# D1H register map
Vendor: Allwinner; File version: 1.0
Registers are 32-bit, read-write, reset 0x0 unless marked. A register's access mark holds for its fields unless they carry their own. Offsets are from the block's base; [hi:lo] are bit positions; {n}, {i} and the like mark numbered series; 'fields as' and 'values as' point back to an identical list; <NAME> marks a mode.

## AUDIO_CODEC
Base 0x02030000
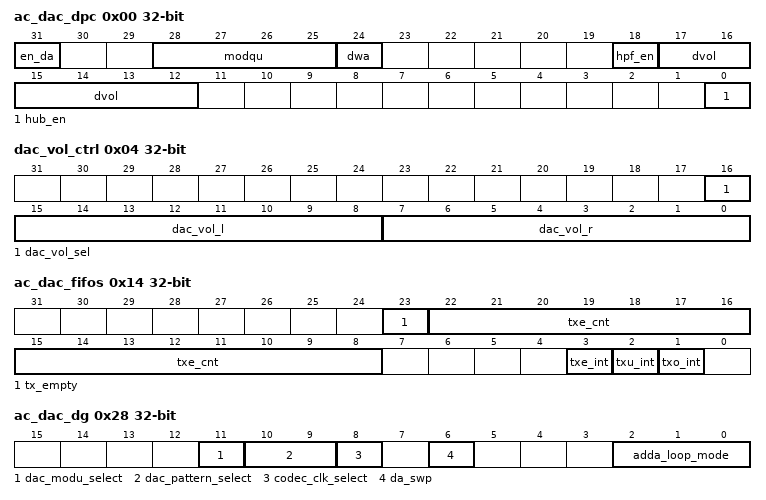
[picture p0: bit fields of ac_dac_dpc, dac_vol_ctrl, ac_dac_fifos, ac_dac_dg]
0x00 ac_dac_dpc — DAC Digital Part Control Register
  [31] en_da — DAC Digital Part Enable
    0=DISABLE; 1=ENABLE
  [28:25] modqu — Internal DAC Quantization Levels. . Levels = [7*(21 + MODQU[3:0])]/128 . Default levels = 7*21/128 = 1.15
  [24] dwa — DWA Function Disable
    0=DISABLE; 1=ENABLE
  [18] hpf_en — High Pass Filter Enable
    0=DISABLE; 1=ENABLE
  [17:12] dvol — Digital Volume Control: DVC . ATT = DVC[5:0] * (-1.16 dB) . 64 steps, -1.16 dB/step
  [0] hub_en — Audio Hub Enable . The bit takes effect only when the EN_DA is set to 1. . System Domain: Audio Codec/I2S0/I2S1/I2S2/OWA TXFIFO Hub Enable.
    0=DISABLE; 1=ENABLE
0x04 dac_vol_ctrl — DAC Volume Control Register
  [16] dac_vol_sel — DAC Volume Control Selection Enable
    0=DISABLE; 1=ENABLE
  [15:8] dac_vol_l — DAC left channel volum (-119.25 dB to 71.25 dB, 0.75 dB/Step) . 0x00: Mute . 0x01: -119.25 dB ... . 0x9F = -0.75 dB . 0xA0 = 0 dB . 0xA1 = 0.75 dB ... . 0xFF = 71.25 dBe
  [7:0] dac_vol_r — DAC right channel volum (-119.25 dB to 71.25 dB, 0.75 dB/Step) . 0x00: Mute . 0x01: -119.25 dB ... . 0x9F = -0.75 dB . 0xA0 = 0 dB . 0xA1 = 0.75 dB ... . 0xFF = 71.25 dBe
0x10 ac_dac_fifoc — DAC FIFO Control Register
  [31:29] dac_fs — Sample Rate of DAC
    0=FS48K; 1=FS32K; 2=FS24K; 3=FS16K; 4=FS12K; 5=FS8K; 6=FS192K; 7=FS96K
  [28] fir_ver — FIR Version
    0=TAP_64; 1=TAP_32
  [26] send_last — Audio sample select when TX FIFO underrun
    0=ZERO; 1=LAST
  [25:24] fifo_mode
    0=BIG_ENDIAN; 1=LITTLE_ENDIAN
  [14:8] dac_drq_clr_cnt — DAC DRQ clear count
    0=WLEVEL; 1=N4; 2=N8; 3=N16
  [14:8] tx_trig_level — TX FIFO Empty Trigger Level
  [6] dac_mono_en — DAC Mono Enable
    0=STEREO; 1=MONO
  [5] tx_sample_bits — Transmitting Audio Sample Resolution
    0=BITS_16; 1=BITS_20
  [4] dac_drq_en — DAC FIFO Empty DRQ Enable
    0=DISABLE; 1=ENABLE
  [3] dac_irq_en — DAC FIFO Empty IRQ Enable
    0=DISABLE; 1=ENABLE
  [2] fifo_underrun_irq_en — DAC FIFO Underrun IRQ Enable
    0=DISABLE; 1=ENABLE
  [1] fifo_overrun_irq_en — DAC FIFO Overrun IRQ Enable
    0=DISABLE; 1=ENABLE
  [0] fifo_flush — DAC FIFO Flush
    0=SELF_CLEAR; 1=FLUSH
0x14 ac_dac_fifos — DAC FIFO Status Register
  [23] tx_empty ro — TX FIFO Empty
    0=NO_ROOM; 1=ROOM
  [22:8] txe_cnt ro — TX FIFO Empty Space Word Counter
  [3] txe_int — TX FIFO Empty Pending Interrupt
    0=NO_PENDING; 1=PENDING
  [2] txu_int — TX FIFO Underrun Pending Interrupt
    0=NO_PENDING; 1=PENDING
  [1] txo_int — TX FIFO Overrun Pending Interrupt
    0=NO_PENDING; 1=PENDING
0x20 ac_dac_txdata wo — DAC TX DATA Register
  [31:0] tx_data — Write the transmitting left and right channel sample data to this register one by one. Write the left channel sample data first and then the right channel sample.
0x24 ac_dac_cnt — DAC TX FIFO Counter Register
  [31:0] tx_cnt — TX Sample Counter . The audio sample number of sending into TXFIFO. . When one sample is put into TXFIFO by DMA or by host IO, the TX sample counter register increases by one. The TX sample counter register can be set to any initial valve at any time. After being updated by the initial value, the counter register should count from this initial value.
0x28 ac_dac_dg — DAC Debug Register
  [11] dac_modu_select — DAC Modulator Debug Mode
    0=NORMAL; 1=DEBUG
  [10:9] dac_pattern_select
    0=NORMAL (Normal (Audio sample from TX FIFO)); 1=SIN6 (-6 dB Sin wave); 2=SIN60 (-60 dB Sin wave); 3=SILENT (Silent wave)
  [8] codec_clk_select — CODEC Clock Source Select
    0=PLL (CODEC clock from PLL); 1=OSC (CODEC clock from OSC (for Debug))
  [6] da_swp — DAC Output Channel Swap Enable
    0=DISABLE; 1=ENABLE
  [2:0] adda_loop_mode — ADDA Loop Mode Select
    0=DISABLE; 1=ADC12 (ADDA LOOP MODE DACL/DACR is connected to ADC1/ADC2); 2=ADC3 (ADDA LOOP MODE DACL/DACR is connected to ADC3)
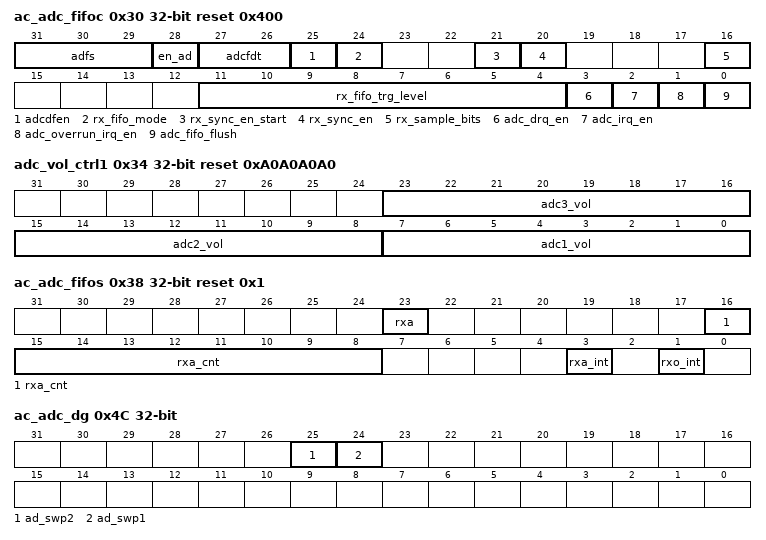
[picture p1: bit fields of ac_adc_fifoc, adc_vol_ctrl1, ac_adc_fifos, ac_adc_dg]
0x30 ac_adc_fifoc reset 0x400 — ADC FIFO Control Register
  [31:29] adfs — Sample Rate of ADC . 44.1 kHz/22.05 kHz/11.025 kHz can be supported by Audio PLL Configure Bit.
    0=48KHZ; 2=24KHZ; 4=12KHZ; 1=32KHZ; 3=16KHZ; 5=8KHZ; 7=R_ESERVED
  [28] en_ad — ADC Digital Part Enable
    0=DISABLED; 1=ENABLED
  [27:26] adcfdt — ADC FIFO delay time for writing data after EN_AD
    0=5_MS; 1=10_MS; 2=20_MS; 3=30_MS
  [25] adcdfen — ADC FIFO delay function for writing data after EN_AD
    0=DISABLED; 1=ENABLED
  [24] rx_fifo_mode — RX FIFO Output Mode (Mode 0, 1) . For 20-bit received audio sample: . Mode 0: RXDATA[31:0] = {FIFO_O[19:0], 12'h0} . Mode 1: RXDATA[31:0] = {12{FIFO_O[19]}, FIFO_O[19:0]} . For 16-bit received audio sample: . Mode 0: RXDATA[31:0] = {FIFO_O[19:4], 16'h0} . Mode 1: RXDATA[31:0] = {16{FIFO_O[19]}, FIFO_O[19:4]}
    0=E_XPANDING_ZERO (Expanding '0' at LSB of TX FIFO register); 1=E_XPANDING_SIGN (Expanding received sample sign bit at MSB of TX FIFO register)
  [21] rx_sync_en_start — The bit takes effect only when RX_SYNC_EN is set to 1. System Domain: Audio codec/I2S0/I2S1/I2S2/DMIC/OWA RX Synchronize Enable Start.
    0=DISABLED; 1=ENABLED
  [20] rx_sync_en — Audiocodec RX Synchronize Enable
    0=DISABLED; 1=ENABLED
  [16] rx_sample_bits — Receiving Audio Sample Resolution
    0=16_BITS; 1=20_BITS
  [11:4] rx_fifo_trg_level — RX FIFO Trigger Level (RXTL[5:0]) . Interrupt and DMA request trigger level for RX FIFO normal condition IRQ/DRQ generated when WLEVEL > RXTL[5:0]
  [3] adc_drq_en — ADC FIFO Data Available DRQ Enable
    0=DISABLED; 1=ENABLED
  [2] adc_irq_en — ADC FIFO Data Available IRQ Enable
    0=DISABLED; 1=ENABLED
  [1] adc_overrun_irq_en — ADC FIFO Overrun IRQ Enable
    0=DISABLED; 1=ENABLED
  [0] adc_fifo_flush write-clears — ADC FIFO Flush . Write '1' to flush TX FIFO, self clear to '0'.
0x34 adc_vol_ctrl1 reset 0xA0A0A0A0 — ADC Volume Control1 Register
  [8n-1:8n-8] adc{n}_vol (n=1..3) — ADC[i] channel volume (-119.25 dB To 71.25 dB, 0.75 dB/Step)
    0=M_UTE; 1=N_119_25DB (-119.25 dB ...); 160=0DB; 255=71_25DB
0x38 ac_adc_fifos reset 0x1 — ADC FIFO Status Register
  [23] rxa ro — RX FIFO Available
    0=NO_AVAILABLE (No available data in RX FIFO); 1=MORE (More than one sample in RX FIFO (>= 1 word))
  [16:8] rxa_cnt ro — RX FIFO Available Sample Word Counter
  [3] rxa_int write-1-clears — RX FIFO Data Available Pending Interrupt
    0=NO_PENDING (No Pending IRQ); 1=PENDING (Data Available Pending IRQ . Write '1' to clear this interrupt or automatic clear if the interrupt condition fails.)
  [1] rxo_int write-1-clears — RX FIFO Overrun Pending Interrupt
    0=NO_PENDING (No Pending IRQ); 1=PENDING (FIFO Overrun Pending IRQ . Write '1' to clear this interrupt.)
0x40 ac_adc_rxdata — ADC RX Data Register
  [31:0] rx_data ro — RX Sample . The host can get one sample by reading this register. The left channel sample data comes first and then the right channel sample.
0x44 ac_adc_cnt — ADC RX Counter Register
  [31:0] rx_cnt — RX Sample Counter . The audio sample number of writing into RXFIFO. When one sample is written by Digital Audio Engine, the RX sample counter register increases by one. The RX sample counter register can be set to any initial valve at any time. After being updated by the initial value, the counter register should count from this initial value.
0x4C ac_adc_dg — ADC Debug Register
  [25] ad_swp2 — ADC output channel swap enable (for digital filter)
    0=DISABLED; 1=ENABLED
  [24] ad_swp1 — ADC output channel swap enable (for digital filter)
    0=DISABLED; 1=ENABLED
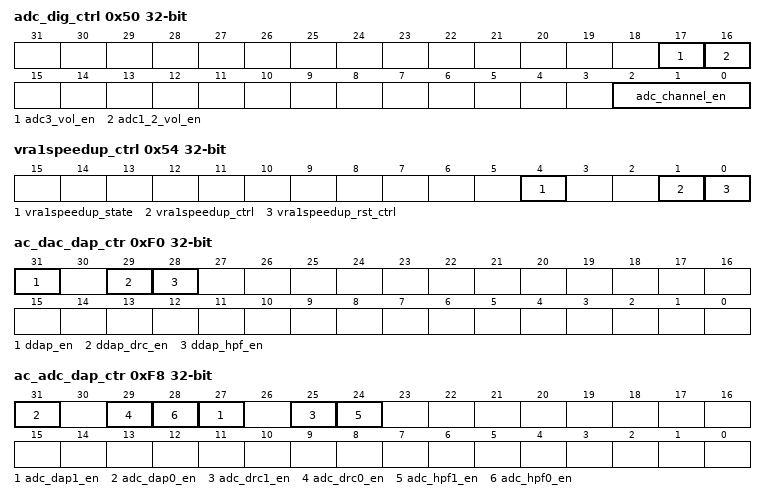
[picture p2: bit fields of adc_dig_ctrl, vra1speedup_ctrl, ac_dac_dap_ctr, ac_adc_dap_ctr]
0x50 adc_dig_ctrl — ADC Digtial Control Register
  [17] adc3_vol_en — ADC3 Volume Control Enable
    0=DISABLED; 1=ENABLED
  [16] adc1_2_vol_en — ADC1/2 Volume Control Enable
    0=DISABLED; 1=ENABLED
  [2:0] adc_channel_en — Bit 3: ADC4 enabled . Bit 2: ADC3 enabled . Bit 1: ADC2 enabled . Bit 0: ADC1 enabled
0x54 vra1speedup_ctrl — VRA1 Speedup Down Control Register
  [4] vra1speedup_state ro — Only if VAR1SPEEDUP_Further_CTRL (0x310[22]) is set 0, VAR1Speedup Down State is valid.
    0=NOT_WORK (VAR1Speedup_Down does not work.); 1=WORK (VAR1Speedup_Down works.)
  [1] vra1speedup_ctrl — VAR1Speedup Down Manual Control Enable
    0=DISABLED (Disabled. . VAR1Speedup Down converts to 1 after the bus rst releases 32 ms.); 1=ENABLED (Enabled. . VAR1Speedup Down converts to 1 immediately.)
  [0] vra1speedup_rst_ctrl — VAR1Speedup Down RST Manual Control Enable
    0=DISABLED (Disabled. . VAR1Speedup Down converts to 1 after the bus rst releases 32 ms.); 1=ENABLED (Enabled. . VAR1Speedup Down reset 0 immediately.)
0xF0 ac_dac_dap_ctr — DAC DAP Control Register
  [31] ddap_en — DAP for DRC enable
    0=BYPASSED; 1=ENABLED
  [29] ddap_drc_en — DRC enable control
    0=DISABLED; 1=ENABLED
  [28] ddap_hpf_en — HPF enable control
    0=DISABLED; 1=ENABLED
0xF8 ac_adc_dap_ctr — ADC DAP Control Register
  [27] adc_dap{x}_en (x=1,0; step 4) — DAP[i] for ADC enable . DAP0 control ADC1/2 . DAP1 control ADC3
    0=BYPASSED; 1=ENABLED
  [25] adc_drc{x}_en (x=1,0; step 4) — ADC DRC[i] enable control
    0=DISABLED; 1=ENABLED
  [24] adc_hpf{x}_en (x=1,0; step 4) — ADC HPF[i] enable control
    0=DISABLED; 1=ENABLED
0x100 ac_dac_drc_hhpfc reset 0xFF — DAC DRC High HPF Coef Register
  [10:0] hhpfc — HPF coefficient setting and the data is 3.24 format.
0x104 ac_dac_drc_lhpfc reset 0xFAC1 — DAC DRC Low HPF Coef Register
  [15:0] lhpfc — HPF coefficient setting and the data is 3.24 format.
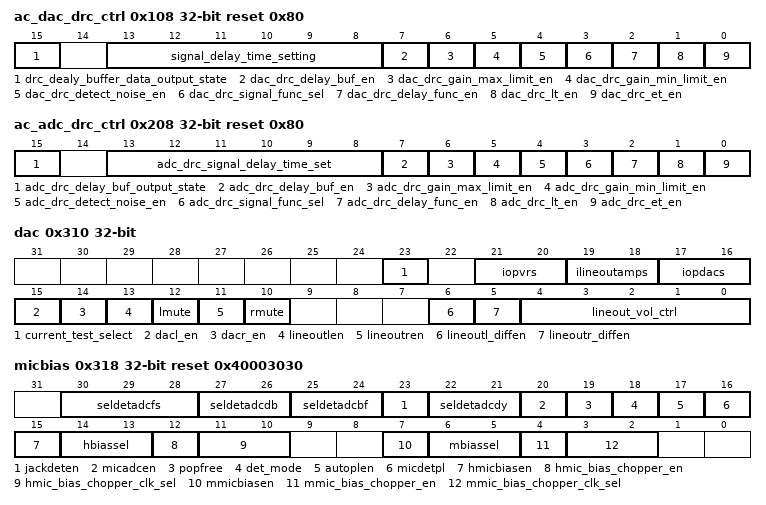
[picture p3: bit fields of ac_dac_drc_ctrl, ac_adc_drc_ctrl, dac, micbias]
0x108 ac_dac_drc_ctrl reset 0x80 — DAC DRC Control Register
  [15] drc_dealy_buffer_data_output_state ro — DRC delay buffer data output state when The DRC delay function is enabled and the DRC function is disabled. After disabling the DRC function and this bit goes to 0, write the DRC delay function bit to 0.
    0=NOT_COMPLETED; 1=COMPLETED
  [13:8] signal_delay_time_setting — Signal delay time setting . Delay time = 8*(n + 1) fs, n less than 30 . When the delay function is disabled, the signal delay time is unused.
  [7] dac_drc_delay_buf_en — The delay buffer use or not when the DRC is disabled and the DRC buffer data output completely.
    0=D_O_NOT_USE_THE_BUFFER; 1=U_SE_THE_BUFFER
  [6] dac_drc_gain_max_limit_en — DRC gain max limit enable
    0=DISABLED; 1=ENABLED
  [5] dac_drc_gain_min_limit_en — DRC gain min limit enable When this function is enabled, it will overwrite the noise detect function.
    0=DISABLED; 1=ENABLED
  [4] dac_drc_detect_noise_en — Control the DRC to detect noise when ET is enabled.
    0=DISABLED; 1=ENABLED
  [3] dac_drc_signal_func_sel — Signal function select . When the signal function selects the Peak filter, the RMS parameter is unused. (AC_DRC_LRMSHAT, AC_DRC_LRMSLAT, AC_DRC_LRMSHAT, AC_DRC_LRMSLAT) . When the signal function selects the RMS filter, the Peak filter parameter is unused. (AC_DRC_LPFHAT, AC_DRC_LPFLAT, AC_DRC_RPFHAT, AC_DRC_RPFLAT, AC_DRC_LPFHRT, AC_DRC_LPFLRT, AC_DRC_RPFHRT, and AC_DRC_RPFLRT)
    0=RMS (RMS filter); 1=P_EAK (Peak filter)
  [2] dac_drc_delay_func_en — Delay function enable
    0=DISABLED; 1=ENABLED (Enabled . When the bit is disabled, the signal delay time is unused.)
  [1] dac_drc_lt_en — DRC LT enable
    0=DISABLED; 1=ENABLED (Enabled . When the bit is disabled, Kl and OPL parameter is unused.)
  [0] dac_drc_et_en — DRC ET enable
    0=DISABLED; 1=ENABLED (Enabled . When the bit is disabled, Ke and OPE parameter is unused.)
0x10C ac_dac_drc_lpfhat reset 0xB — DAC DRC Left Peak Filter High Attack Time Coef Register
  [10:0] dac_drc_lpfhat — The left peak filter attack time parameter setting, which is determined by the equation that AT = 1-exp (-2.2Ts/ta). The format is 3.24. (The default value is 1 ms)
0x110 ac_dac_drc_lpflat reset 0x77BF — DAC DRC Left Peak Filter Low Attack Time Coef Register
  [15:0] dac_drc_lpflat — The left peak filter attack time parameter setting, which is determined by the equation that AT = 1-exp (-2.2Ts/ta). The format is 3.24. (The default value is 1 ms)
0x114 ac_dac_drc_rpfhat reset 0xB — DAC DRC Right Peak Filter High Attack Time Coef Register
  [15:0] dac_drc_rpfhat — The right peak filter attack time parameter setting, which is determined by the equation that AT = 1-exp (-2.2Ts/ta). The format is 3.24. (The default value is 1 ms)
0x118 ac_dac_drc_rpflat reset 0x77BF — DAC DRC Peak Filter Low Attack Time Coef Register
  [15:0] dac_drc_rpflat — The left peak filter attack time parameter setting, which is determined by the equation that AT = 1-exp (-2.2Ts/ta). The format is 3.24. (The default value is 1 ms)
0x11C ac_dac_drc_lpfhrt reset 0xFF — DAC DRC Left Peak Filter High Release Time Coef Register
  [10:0] dac_drc_lpfhrt — The left peak filter release time parameter setting, which is determined by the equation that RT = exp (-2.2Ts/tr). The format is 3.24. (The default value is 100 ms)
0x120 ac_dac_drc_lpflrt reset 0xE1F8 — DAC DRC Left Peak Filter Low Release Time Coef Register
  [15:0] dac_drc_lpflrt — The left peak filter release time parameter setting, which is determined by the equation that RT = exp (-2.2Ts/tr). The format is 3.24. (The default value is 100 ms)
0x124 ac_dac_drc_rpfhrt reset 0xFF — DAC DRC Right Peak filter High Release Time Coef Register
  [15:0] dac_drc_rpfhrt — The right peak filter release time parameter setting, which is determined by the equation that RT = exp (-2.2Ts/tr). The format is 3.24. (The default value is 100 ms)
0x128 ac_dac_drc_rpflrt reset 0xE1F8 — DAC DRC Right Peak filter Low Release Time Coef Register
  [15:0] dac_drc_rpflrt — The right peak filter release time parameter setting, which is determined by the equation that AT = exp(-2.2Ts/tr). The format is 3.24. (The default value is 100 ms)
0x12C ac_dac_drc_lrmshat reset 0x1 — DAC DRC Left RMS Filter High Coef Register
  [10:0] dac_drc_lrmshat — The left RMS filter average time parameter setting, which is determined by the equation that AT = 1-exp (-2.2Ts/tav). The format is 3.24. (The default value is 10 ms)
0x130 ac_dac_drc_lrmslat reset 0x2BAF — DAC DRC Left RMS Filter Low Coef Register
  [15:0] dac_drc_lrmslat — The left RMS filter average time parameter setting, which is determined by the equation that AT = 1-exp (-2.2Ts/tav). The format is 3.24. (The default value is 10 ms)
0x134 ac_dac_drc_rrmshat reset 0x2BAF — DAC DRC Right RMS Filter High Coef Register
  [15:0] dac_drc_rrmshat — The right RMS filter average time parameter setting, which is determined by the equation that AT = 1-exp (-2.2Ts/tav). The format is 3.24. (The default value is 10 ms)
0x138 ac_dac_drc_rrmslat reset 0x2BAF — DAC DRC Right RMS Filter Low Coef Register
  [15:0] dac_drc_rrmslat — The right RMS filter average time parameter setting, which is determined by the equation that AT = 1-exp (-2.2Ts/tav). The format is 3.24. (The default value is 10 ms)
0x13C ac_dac_drc_hct reset 0x6A4 — DAC DRC Compressor Threshold High Setting Register
  [15:0] dac_drc_hct — The compressor threshold setting, which is set by the equation that CTin = -CT/6.0206. The format is 8.24. (The default value is - 40 dB)
0x140 ac_dac_drc_lct reset 0xD3C0 — DAC DRC Compressor Slope High Setting Register
  [15:0] dac_drc_lct — The compressor threshold setting, which is set by the equation that CTin = -CT/6.0206. The format is 8.24. (The default value is - 40 dB)
0x144 ac_dac_drc_hkc reset 0x80 — DAC DRC Compressor Slope High Setting Register
  [15:0] dac_drc_hkc — The slope of the compressor, which is determined by the equation that Kc = 1/R. R is the ratio of the compressor, which is always an integer. The format is 8.24. (The default value is 2:1)
0x148 ac_dac_drc_lkc — DAC DRC Compressor Slope Low Setting Register
  [15:0] dac_drc_lkc — The slope of the compressor, which is determined by the equation that Kc = 1/R. R is the ratio of the compressor, which is always an integer. The format is 8.24. (The default value is 2:1)
0x14C ac_dac_drc_hopc reset 0xF95B — DAC DRC Compressor High Output at Compressor Threshold Register
  [15:0] dac_drc_hopc — The output of the compressor, which is determined by the equation -OPC/6.0206. The format is 8.24 (The default value is -40 dB)
0x150 ac_dac_drc_lopc reset 0x2C3F — DAC DRC Compressor Low Output at Compressor Threshold Register
  [15:0] dac_drc_lopc — The output of the compressor, which is determined by the equation OPC/6.0206. The format is 8.24. (The default value is -40 dB)
0x154 ac_dac_drc_hlt reset 0x1A9 — DAC DRC Limiter Threshold High Setting Register
  [15:0] dac_drc_hlt — The limiter threshold setting, which is set by the equation that LTin = -LT/6.0206, The format is 8.24. (The default value is -10 dB)
0x158 ac_dac_drc_llt reset 0x34F0 — DAC DRC Limiter Threshold Low Setting Register
  [15:0] dac_drc_llt — The limiter threshold setting, which is set by the equation that LTin = -LT/6.0206. The format is 8.24. (The default value is -10 dB)
0x15C ac_dac_drc_hkl reset 0x5 — DAC DRC Limiter Slope High Setting Register
  [15:0] dac_drc_hkl — The slope of the limiter which is determined by the equation that Kl = 1/R. R is the ratio of the limiter, which is always an integer. The format is 8.24. (The default value is <50:1>)
0x160 ac_dac_drc_lkl reset 0x1EB8 — DAC DRC Limiter Slope Low Setting Register
  [15:0] dac_drc_lkl — The slope of the limiter, which is determined by the equation that Kl = 1/R. R is the ratio of the limiter, which is always an integer. The format is 8.24. (The default value is <50:1>)
0x164 ac_dac_drc_hopl reset 0xFBD8 — DAC DRC Limiter High Output at Limiter Threshold
  [15:0] dac_drc_hopl — The output of the limiter, which is determined by equation OPT/6.0206. The format is 8.24. (The default value is -25 dB)
0x168 ac_dac_drc_lopl reset 0xFBA7 — DAC DRC Limiter Low Output at Limiter Threshold
  [15:0] dac_drc_lopl — The output of the limiter, which is determined by equation OPT/6.0206. The format is 8.24. (The default value is -25 dB)
0x16C ac_dac_drc_het reset 0xBA0 — DAC DRC Expander Threshold High Setting Register
  [15:0] dac_drc_het — The expander threshold setting, which is set by the equation that ETin = -ET/6.0206. The format is 8.24. (The default value is -70 dB)
0x170 ac_dac_drc_let reset 0x7291 — DAC DRC Expander Threshold Low Setting Register
  [15:0] dac_drc_let — The expander threshold setting, which is set by the equation that ETin = -ET/6.0206. The format is 8.24. (The default value is -70 dB)
0x174 ac_dac_drc_hke reset 0x500 — DAC DRC Expander Slope High Setting Register
  [13:0] dac_drc_hke — The slope of the expander, which is determined by the equation that Ke = 1/R. R is the ratio of the expander, which is always an integer and the ke must larger than 50. The format is 8.24. (The default value is <1:5>)
0x178 ac_dac_drc_lke — DAC DRC Expander Slope Low Setting Register
  [15:0] dac_drc_lke — The slope of the expander, which is determined by the equation that Ke = 1/R. R is the ratio of the expander, which is always an integer and the ke must larger than 50. The format is 8.24. (The default value is <1:5>)
0x17C ac_dac_drc_hope reset 0xF45F — DAC DRC Expander High Output at Expander Threshold
  [15:0] dac_drc_hope — The output of the expander, which is determined by equation OPE/6.0206. The format is 8.24. (The default value is -70 dB)
0x180 ac_dac_drc_lope reset 0x8D6E — DAC DRC Expander Low Output at Expander Threshold
  [15:0] dac_drc_lope — The output of the expander which is determined by equation OPE/6.0206. The format is 8.24. (The default value is -70 dB)
0x184 ac_dac_drc_hkn reset 0x100 — DAC DRC Linear Slope High Setting Register
  [15:0] dac_drc_hkn — The slope of the linear, which is determined by the equation that Kn = 1/R. R is the ratio of the linear, which is always an integer. The format is 8.24. (The default value is <1:1>)
0x188 ac_dac_drc_lkn — DAC DRC Linear Slope Low Setting Register
  [15:0] dac_drc_lkn — The slope of the linear, which is determined by the equation that Kn = 1/R. R is the ratio of the linear, which is always an integer. The format is 8.24. (The default value is <1:1>)
0x18C ac_dac_drc_sfhat reset 0x2 — DAC DRC Smooth filter Gain High Attack Time Coef Register
  [10:0] dac_drc_sfhat — The smooth filter attack time parameter setting, which is determined by the equation that AT = 1-exp (-2.2Ts/tr). The format is 3.24. (The default value is 5 ms)
0x190 ac_dac_drc_sflat reset 0x5600 — DAC DRC Smooth filter Gain Low Attack Time Coef Register
  [15:0] dac_drc_sflat — The smooth filter attack time parameter setting, which is determined by the equation that AT = 1-exp (-2.2Ts/tr). The format is 3.24. (The default value is 5 ms)
0x194 ac_dac_drc_sfhrt — DAC DRC Smooth filter Gain High Release Time Coef Register
  [10:0] dac_drc_sfhrt — The gain smooth filter release time parameter setting, which is determined by the equation that RT = 1-exp (-2.2Ts/tr). The format is 3.24. (The default value is 200 ms)
0x198 ac_dac_drc_sflrt reset 0xF04 — DAC DRC Smooth filter Gain Low Release Time Coef Register
  [15:0] dac_drc_sflrt — The gain smooth filter release time parameter setting, which is determined by the equation that RT = 1-exp (-2.2Ts/tr). The format is 3.24. (The default value is 200 ms)
0x19C ac_dac_drc_mxghs reset 0xFE56 — DAC DRC MAX Gain High Setting Register
  [15:0] dac_drc_mxghs — The max gain setting, which is determined by equation MXG =MXG/6.0206. The format is 8.24 and must -20 dB < MXG < 30 dB (The default value is -10 dB)
0x1A0 ac_dac_drc_mxgls reset 0xCB0F — DAC DRC MAX Gain Low Setting Register
  [15:0] dac_drc_mxgls — The max gain setting, which is determined by equation MXG =MXG/6.0206. The format is 8.24 and must -20 dB < MXG < 30 dB (The default value is -10 dB)
0x1A4 ac_dac_drc_mnghs reset 0xF95B — DAC DRC MIN Gain High Setting Register
  [15:0] dac_drc_mnghs — The min gain setting, which is determined by equation MXG =MXG/6.0206. The format is 8.24 and must -60 dB ≤ MNG ≤ -40 dB (The default value is -40 dB)
0x1A8 ac_dac_drc_mngls reset 0x2C3F — DAC DRC MIN Gain Low Setting Register
  [15:0] dac_drc_mngls — The min gain setting, which is determined by equation MXG =MNG/6.0206. The format is 8.24 and must -60 dB ≤ MNG ≤ -40 dB (The default value is -40 dB)
0x1AC ac_dac_drc_epshc — DAC DRC Expander Smooth Time High Coef Register
  [10:0] dac_drc_epshc — The gain smooth filter release and attack time parameter setting in expander region, which are determined by the equation that RT = 1-exp (-2.2Ts/tr). The format is 3.24. (The default value is 30 ms)
0x1B0 ac_dac_drc_epslc reset 0x640C — DAC DRC Expander Smooth Time Low Coef Register
  [15:0] dac_drc_epslc — The gain smooth filter release and attack time parameter setting in expander region, which are determined by the equation that RT = 1-exp (-2.2Ts/tr). The format is 3.24. (The default value is 30 ms)
0x1B8 ac_dac_drc_hpfhgain reset 0x100 — DAC DRC HPF Gain High Coef Register
  [10:0] dac_drc_hpfhgain — The gain of HPF coefficient. The format is 3.24. (gain = 1)
0x1BC ac_dac_drc_hpflgain — DAC DRC HPF Gain Low Coef Register
  [15:0] dac_drc_hpflgain — The gain of HPF coefficient. The format is 3.24. (gain = 1)
0x200 ac_adc_drc_hhpfc reset 0xFF — ADC DRC High HPF Coef Register
  [10:0] hhpfc — HPF coefficient setting and the data is 3.24 format.
0x204 ac_adc_drc_lhpfc reset 0xFAC1 — ADC DRC Low HPF Coef Register
  [15:0] lhpfc — HPF coefficient setting and the data is 3.24 format.
0x208 ac_adc_drc_ctrl reset 0x80 — ADC DRC Control Register
  [15] adc_drc_delay_buf_output_state ro — DRC delay buffer data output state when The DRC delay function is enabled and the DRC function is disabled. After disabled DRC function and this bit goes to 0, the user should write the DRC delay function bit to 0.
    0=NOT_COMPLETED; 1=COMPLETED
  [13:8] adc_drc_signal_delay_time_set — Signal delay time setting . Delay time = 8*(n + 1) fs, n < 6'h30 . When the delay function is disabled, the signal delay time is unused.
  [7] adc_drc_delay_buf_en — The delay buffer use or not when the DRC is disabled and the DRC buffer data output completely.
    0=D_O_NOT_USE_THE_BUFFER; 1=U_SE_THE_BUFFER
  [6] adc_drc_gain_max_limit_en — DRC gain max limit enable
    0=DISABLED; 1=ENABLED
  [5] adc_drc_gain_min_limit_en — DRC gain min limit enable . When this fuction is enabled, it will overwrite the noise detect function.
    0=DISABLED; 1=ENABLED
  [4] adc_drc_detect_noise_en — Control the DRC to detect noise when ET is enabled
    0=DISABLED; 1=ENABLED
  [3] adc_drc_signal_func_sel — Signal function select . When the signal function selects the Peak filter, the RMS parameter is unused. (AC_DRC_LRMSHAT, AC_DRC_LRMSLAT, AC_DRC_LRMSHAT, and AC_DRC_LRMSLAT) . When the signal function selects the RMS filter, the Peak filter parameter is unused. (AC_DRC_LPFHAT, AC_DRC_LPFLAT, AC_DRC_RPFHAT, AC_DRC_RPFLAT, AC_DRC_LPFHRT, AC_DRC_LPFLRT, AC_DRC_RPFHRT, and AC_DRC_RPFLRT)
    0=RMS (RMS filter); 1=P_EAK (Peak filter)
  [2] adc_drc_delay_func_en — Delay function enable . When the bit is disabled, the signal delay time is unused.
    0=DISABLED; 1=ENABLED
  [1] adc_drc_lt_en — DRC LT enable . When the bit is disabled, Kl and OPL parameter is unused.
    0=DISABLED; 1=ENABLED
  [0] adc_drc_et_en — DRC ET enable . When the bit is disabled, Ke and OPE parameter is unused.
    0=DISABLED; 1=ENABLED
0x20C ac_adc_drc_lpfhat reset 0xB — ADC DRC Left Peak Filter High Attack Time Coef Register
  [10:0] adc_drc_lpfhat — The left peak filter attack time parameter setting, which is determined by the equation that AT = 1-exp (-2.2Ts/ta). The format is 3.24. (The default value is 1 ms)
0x210 ac_adc_drc_lpflat reset 0x77BF — ADC DRC Left Peak Filter Low Attack Time Coef Register
  [15:0] adc_drc_lpflat — The left peak filter attack time parameter setting, which is determined by the equation that AT = 1-exp (-2.2Ts/ta). The format is 3.24. (The default value is 1 ms)
0x214 ac_adc_drc_rpfhat reset 0xB — ADC DRC Right Peak Filter High Attack Time Coef Register
  [15:0] adc_drc_rpfhat — The right peak filter attack time parameter setting, which is determined by the equation that AT = 1-exp (-2.2Ts/ta). The format is 3.24. (The default value is 1 ms)
0x218 ac_adc_drc_rpflat reset 0x77BF — ADC DRC Right Peak Filter Low Attack Time Coef Register
  [15:0] adc_drc_rpflat — The right peak filter attack time parameter setting, which is determined by the equation that AT = 1-exp (-2.2Ts/ta). The format is 3.24. (The default value is 1 ms)
0x21C ac_adc_drc_lpfhrt reset 0xFF — ADC DRC Left Peak Filter High Release Time Coef Register
  [10:0] adc_drc_lpfhrt — The left peak filter release time parameter setting, which is determined by the equation that RT = exp (-2.2Ts/tr). The format is 3.24. (The default value is 100 ms)
0x220 ac_adc_drc_lpflrt reset 0xE1F8 — ADC DRC Left Peak Filter Low Release Time Coef Register
  [15:0] adc_drc_lpflrt — The left peak filter release time parameter setting, which is determined by the equation that RT = exp (-2.2Ts/tr). The format is 3.24. (The default value is 100 ms)
0x224 ac_adc_drc_rpfhrt reset 0xFF — ADC DRC Right Peak Filter High Release Time Coef Register
  [15:0] adc_drc_rpfhrt — The right peak filter release time parameter setting, which is determined by the equation that RT = exp (-2.2Ts/tr). The format is 3.24. (The default value is 100 ms)
0x228 ac_adc_drc_rpflrt reset 0xE1F8 — ADC DRC Right Peak Filter Low Release Time Coef Register
  [15:0] adc_drc_rpflrt — The right peak filter release time parameter setting, which is determined by the equation that RT = exp (-2.2Ts/tr). The format is 3.24. (The default value is 100 ms)
0x22C ac_adc_drc_lrmshat reset 0x1 — ADC DRC Left RMS Filter High Coef Register
  [10:0] adc_drc_lrmshat — The left RMS filter average time parameter setting, which is determined by the equation that AT = 1-exp (-2.2Ts/tav). The format is 3.24. (The default value is 10 ms)
0x230 ac_adc_drc_lrmslat reset 0x2BAF — ADC DRC Left RMS Filter Low Coef Register
  [15:0] adc_drc_lrmslat — The left RMS filter average time parameter setting, which is determined by the equation that AT = 1-exp (-2.2Ts/tav). The format is 3.24. (The default value is 10 ms)
0x234 ac_adc_drc_rrmshat reset 0x1 — ADC DRC Right RMS Filter High Coef Register
  [10:0] adc_drc_rrmshat — The right RMS filter average time parameter setting, which is determined by the equation that AT = 1-exp (-2.2Ts/tav). The format is 3.24. (The default value is 10 ms)
0x238 ac_adc_drc_rrmslat reset 0x2BAF — ADC DRC Right RMS Filter Low Coef Register
  [15:0] adc_drc_rrmslat — The right RMS filter average time parameter setting, which is determined by the equation that AT = 1-exp (-2.2Ts/tav). The format is 3.24. (The default value is 10 ms)
0x23C ac_adc_drc_hct reset 0x6A4 — ADC DRC Compressor Threshold High Setting Register
  [15:0] adc_drc_hct — The compressor threshold setting, which is set by the equation that CTin = -CT/6.0206. The format is 8.24. (The default value is - 40 dB)
0x240 ac_adc_drc_lct reset 0xD3C0 — ADC DRC Compressor Slope High Setting Register
  [15:0] adc_drc_lct — The compressor threshold setting, which is set by the equation that CTin = -CT/6.0206. The format is 8.24. (The default value is - 40 dB)
0x244 ac_adc_drc_hkc reset 0x80 — ADC DRC Compressor Slope High Setting Register
  [15:0] adc_drc_hkc — The slope of the compressor which is determined by the equation that Kc = 1/R. R is the ratio of the compressor, which is always an integer. The format is 8.24. (The default value is <2:1>)
0x248 ac_adc_drc_lkc — ADC DRC Compressor Slope Low Setting Register
  [15:0] adc_drc_lkc — The slope of the compressor, which is determined by the equation that Kc = 1/R. R is the ratio of the compressor, which is always an integer. The format is 8.24. (The default value is <2:1>)
0x24C ac_adc_drc_hopc reset 0xF95B — ADC DRC Compressor High Output at Compressor Threshold Register
  [15:0] adc_drc_hopc — The output of the compressor, which is determined by the equation -OPC/6.0206. The format is 8.24. (The default value is -40 dB)
0x250 ac_adc_drc_lopc reset 0x2C3F — ADC DRC Compressor Low Output at Compressor Threshold Register
  [15:0] adc_drc_lopc — The output of the compressor, which is determined by the equation OPC/6.0206. The format is 8.24. (The default value is -40 dB)
0x254 ac_adc_drc_hlt reset 0x1A9 — ADC DRC Limiter Threshold High Setting Register
  [15:0] adc_drc_hlt — The limiter threshold setting, which is set by the equation that LTin = -LT/6.0206. The format is 8.24. (The default value is -10 dB)
0x258 ac_adc_drc_llt reset 0x34F0 — ADC DRC Limiter Threshold Low Setting Register
  [15:0] adc_drc_llt — The limiter threshold setting, which is set by the equation that LTin = -LT/6.0206. The format is 8.24. (The default value is -10 dB)
0x25C ac_adc_drc_hkl reset 0x5 — ADC DRC Limiter Slope High Setting Register
  [13:0] adc_drc_hkl — The slope of the limiter, which is determined by the equation that Kl = 1/R. R is the ratio of the limiter, which is always an integer. The format is 8.24. (The default value is <50:1>)
0x260 ac_adc_drc_lkl reset 0x1EB8 — ADC DRC Limiter Slope Low Setting Register
  [15:0] adc_drc_lkl — The slope of the limiter, which is determined by the equation that Kl = 1/R. R is the ratio of the limiter, which is always an integer. The format is 8.24. (The default value is <50:1>)
0x264 ac_adc_drc_hopl reset 0xFBD8 — ADC DRC Limiter High Output at Limiter Threshold
  [15:0] adc_drc_hopl — The output of the limiter, which is determined by equation OPT/6.0206. The format is 8.24. (The default value is -25 dB)
0x268 ac_adc_drc_lopl reset 0xFBA7 — ADC DRC Limiter Low Output at Limiter Threshold
  [15:0] adc_drc_lopl — The output of the limiter which is determined by equation OPT/6.0206. The format is 8.24. (The default value is -25 dB)
0x26C ac_adc_drc_het reset 0xBA0 — ADC DRC Expander Threshold High Setting Register
  [15:0] adc_drc_het — The expander threshold setting, which is set by the equation that ETin = -ET/6.0206, The format is 8.24. (The default value is -70 dB)
0x270 ac_adc_drc_let reset 0x7291 — ADC DRC Expander Threshold Low Setting Register
  [15:0] adc_drc_let — The expander threshold setting, which is set by the equation that ETin = -ET/6.0206, The format is 8.24. (The default value is -70 dB)
0x274 ac_adc_drc_hke reset 0x500 — ADC DRC Expander Slope High Setting Register
  [15:0] adc_drc_hke — The slope of the expander, which is determined by the equation that Ke = 1/R. R is the ratio of the expander, which is always an integer and the ke must larger than 50. The format is 8.24. (The default value is <1:5>)
0x278 ac_adc_drc_lke — ADC DRC Expander Slope Low Setting Register
  [15:0] adc_drc_lke — The slope of the expander, which is determined by the equation that Ke = 1/R. R is the ratio of the expander, which is always an integer and the ke must be larger than 50. The format is 8.24. (The default value is <1:5>)
0x27C ac_adc_drc_hope reset 0xF45F — ADC DRC Expander High Output at Expander Threshold
  [15:0] adc_drc_hope — The output of the expander, which is determined by equation OPE/6.0206. The format is 8.24. (The default value is -70 dB)
0x280 ac_adc_drc_lope reset 0x8D6E — ADC DRC Expander Low Output at Expander Threshold
  [15:0] adc_drc_lope — The output of the expander, which is determined by equation OPE/6.0206. The format is 8.24. (The default value is -70 dB)
0x284 ac_adc_drc_hkn reset 0x100 — ADC DRC Linear Slope High Setting Register
  [15:0] adc_drc_hkn — The slope of the linear, which is determined by the equation that Kn = 1/R. R is the ratio of the linear, which is always an integer. The format is 8.24. (The default value is <1:1>)
0x288 ac_adc_drc_lkn — ADC DRC Linear Slope Low Setting Register
  [15:0] adc_drc_lkn — The slope of the linear, which is determined by the equation that Kn = 1/R. R is the ratio of the linear, which is always an integer. The format is 8.24. (The default value is <1:1>)
0x28C ac_adc_drc_sfhat reset 0x2 — ADC DRC Smooth filter Gain High Attack Time Coef Register
  [10:0] adc_drc_sfhat — The smooth filter attack time parameter setting, which is determined by the equation that AT = 1-exp (-2.2Ts/tr). The format is 3.24. (The default value is 5 ms)
0x290 ac_adc_drc_sflat reset 0x5600 — ADC DRC Smooth filter Gain Low Attack Time Coef Register
  [15:0] adc_drc_sflat — The smooth filter attack time parameter setting, which is determined by the equation that AT = 1-exp (-2.2Ts/tr). The format is 3.24. (The default value is 5 ms)
0x294 ac_adc_drc_sfhrt — ADC DRC Smooth filter Gain High Release Time Coef Register
  [10:0] adc_drc_sfhrt — The gain smooth filter release time parameter setting, which is determined by the equation that RT = 1-exp (-2.2Ts/tr). The format is 3.24. (The default value is 200 ms)
0x298 ac_adc_drc_sflrt reset 0xF04 — ADC DRC Smooth filter Gain Low Release Time Coef Register
  [15:0] adc_drc_sflrt — The gain smooth filter release time parameter setting, which is determined by the equation that RT = 1-exp (-2.2Ts/tr). The format is 3.24. (The default value is 200 ms)
0x29C ac_adc_drc_mxghs reset 0xFE56 — ADC DRC MAX Gain High Setting Register
  [15:0] adc_drc_mxghs — The max gain setting, which is determined by equation MXG =MXG/6.0206. The format is 8.24 and must -20 dB < MXG < 30 dB (The default value is -10 dB)
0x2A0 ac_adc_drc_mxgls reset 0xCB0F — ADC DRC MAX Gain Low Setting Register
  [15:0] adc_drc_mxgls — The max gain setting, which is determined by equation MXG =MXG/6.0206. The format is 8.24 and must -20 dB < MXG < 30 dB (The default value is -10 dB)
0x2A4 ac_adc_drc_mnghs reset 0xF95B — ADC DRC MIN Gain High Setting Register
  [15:0] adc_drc_mnghs — The min gain setting, which is determined by equation MXG =MXG/6.0206. The format is 8.24 and must -60 dB ≤ MNG ≤ -40 dB (The default value is -40 dB)
0x2A8 ac_adc_drc_mngls reset 0x2C3F — ADC DRC MIN Gain Low Setting Register
  [15:0] adc_drc_mngls — The min gain setting, which is determined by equation MXG =MNG/6.0206. The format is 8.24 and must -60 dB ≤ MNG ≤ -40 dB (The default value is -40 dB)
0x2AC ac_adc_drc_epshc — ADC DRC Expander Smooth Time High Coef Register
  [10:0] adc_drc_epshc — The gain smooth filter release and attack time parameter setting in expander region, which is determined by the equation that RT = 1-exp (-2.2Ts/tr). The format is 3.24. (The default value is 30 ms)
0x2B0 ac_adc_drc_epslc reset 0x640C — ADC DRC Expander Smooth Time Low Coef Register
  [15:0] adc_drc_epslc — The gain smooth filter release and attack time parameter setting in expander region, which is determined by the equation that RT = 1-exp (-2.2Ts/tr). The format is 3.24. (The default value is 30 ms)
0x2B8 ac_adc_drc_hpfhgain reset 0x100 — ADC DRC HPF Gain High Coef Register
  [10:0] adc_drc_hpfhgain — The gain of HPF coefficient setting, which format is 3.24. (gain = 1)
0x2BC ac_adc_drc_hpflgain — ADC DRC HPF Gain Low Coef Register
  [15:0] adc_drc_hpflgain — The gain of HPF coefficient setting, which format is 3.24. (gain = 1)
{0x300+4i} adc{i} (i=0..2) reset 0x1CC055 (reset mask 0xFFFFDFFF) — ADC[i] Analog Control Register
  [31] adc_en — ADC Channel Enable
    0=DISABLED; 1=ENABLED
  [30] mic_pga_en — MIC PGA Enable
    0=DISABLED; 1=ENABLED
  [29] adc_d_itcher_c_ontrol — Dither Control
    0=N_EW_D_ITHER_O_FF; 1=N_EW_D_ITHER_O_N
  [28] mic_sin_en — MIC Single Input Enable
    0=DISABLE; 1=ENABLE
  [27] fminlen — FMINL Enable
    0=DISABLE; 1=ENABLE
  [26] fminlg — FMINL Gain Control
    0=0DB; 1=6DB
  [25:24] dsm_dither_lvl — Dither Level Control (Dither level is positive ralated to the ctrl bits)
    0=N_O (No Level); 1=M_IN (Min Level); 2=M_IDDLE (Middle Level); 3=M_AX (Max Level)
  [23] lineinlen — LINEINL Enable
    0=DISABLE; 1=ENABLE
  [22] lineinlg — LINEINL Gain Control
    0=0DB; 1=6DB
  [21:20] iopbuffer — PGA Vcm Buffer OP Bias Current Select
    {v}={v+6}UA (v=0..3)
  [19:18] adc_pga_ctrl_rcm — ADC PGA Common Mode Input Impedance Control for MICIN
    0=100K (100 kΩ); 1=75K (75 kΩ); 2=50K (50 kΩ); 3=25K (25 kΩ)
  [17:16] adc_pga_in_vcm_ctrl — ADC PGA Common-Mode Voltage Control
    0=900M (900 mV); 1=800M (800 mV); 2=750M (750 mV); 3=700M (700 mV)
  [15:14] iopadc — ADC1-ADC3 Bias Current Select
    {v}={v+1}U ({v+1} uA) (v=0..3)
  [12:8] adc_pga_gain_ctrl — ADC PGA gain settings: . 0x0: 0 dB 0x10: 21 dB . 0x1: 6 dB 0x11: 22 dB . 0x2: 6 dB 0x12: 23 dB . 0x3: 6 dB 0x13: 24 dB . 0x4: 9 dB 0x14: 25 dB . 0x5: 10 dB 0x15: 26 dB . 0x6: 11 dB 0x16: 27 dB . 0x7: 12 dB 0x17: 28 dB . 0x8: 13 dB 0x18: 29 dB . 0x9: 14 dB 0x19: 30 dB . 0xA: 15 dB 0x1A: 31 dB . 0xB: 16 dB 0x1B: 32 dB . 0xC: 17 dB 0x1C: 33 dB . 0xD: 18 dB 0x1D: 34 dB . 0xE: 19 dB 0x1E: 35 dB . 0xF: 20 dB 0x1F: 36 dB
  [7:6] adc_iopaaf — ADC OP AAF Bias Current Select . IOPADC is defined by ADC_REG<15:14> from 1 uA to 4 uA. . For example: ADC_REG<15:14> = 11, IOPADC = 4 uA . 00: 1.50*4 uA = 6 uA . 01: 1.75*4 uA = 7 uA . 10: 2.00*4 uA = 8 uA . 11: 2.25*4 uA = 9 uA
    0=1.50*IOPADC; 1=1.75*IOPADC; 2=2.00*IOPADC; 3=2.25*IOPADC
  [5:4] adc_iopsdm{x} (x=2,1; step 2) — ADC OP SDM Bias Current Select [i] . IOPADC is defined by ADC_REG<15:14> from 1 uA to 4 uA.
    0=1.50*IOPADC; 1=1.75*IOPADC; 2=2.00*IOPADC; 3=2.25*IOPADC
  [1:0] adc_iopmic — ADC OP MIC Bias Current Select . IOPADC is defined by ADC_REG<15:14> from 1 uA to 4 uA.
    0=1.50*IOPADC; 1=1.75*IOPADC; 2=2.00*IOPADC; 3=2.25*IOPADC
0x310 dac — DAC Analog Control Register
  [23] current_test_select — Internal Current Sink Test Enable (from MICIN3P pin)
    0=NORMAL; 1=DEBUG
  [21:20] iopvrs — VRA2 Buffer OP and Headphone Feedback Buffer OP Bias Current Select
    {v}=C{v+6}U (v=0..3)
  [19:18] ilineoutamps — LINEOUT L/R AMP Bias Current Select
    {v}=C{v+6}U (v=0..3)
  [17:16] iopdacs — OPDAC L/R Bias Current Select
    {v}=C{v+6}U (v=0..3)
  [15] dacl_en — DACL Enable
    0=DISABLE; 1=ENABLE
  [14] dacr_en — DACR Enable
    0=DISABLE; 1=ENABLE
  [13] lineoutlen — Left Channel LINEOUT Enable
    0=DISABLE; 1=ENABLE
  [12] lmute — DACL to Left Channel LINEOUT Mute Control
    0=MUTE; 1=UNMUTE
  [11] lineoutren — Right Channel LINEOUT Enable
    0=DISABLE; 1=ENABLE
  [10] rmute — DACR to Right Channel LINEOUT Mute Control
    0=MUTE; 1=UNMUTE
  [6] lineoutl_diffen — Left Channel LINEOUT Output Control
    0=SINGLE; 1=DIFFERENTIAL
  [5] lineoutr_diffen — Right Channel LINEOUT Output Control
    0=SINGLE; 1=DIFFERENTIAL
  [4:0] lineout_vol_ctrl — LINEOUT Volume Control. . Total 30 level from 0x1F to 0x02 with the volume 0 dB to -43.5 dB, -1.5 dB/step, mute when 00000 or 00001
0x318 micbias reset 0x40003030 — MICBIAS Analog Control Register
  [30:28] seldetadcfs — Select sample interval of the ADC sample\\ 2 ^ (SELDETADCFS + 1) ms
  [27:26] seldetadcdb — Select debounce time when jack removal
    0=128_MS; 1=256_MS; 2=512_MS; 3=1024_MS
  [25:24] seldetadcbf — Select the time to enable HBIAS before MICADC work
    0=2_MS; 1=4_MS; 2=8_MS; 3=16_MS
  [23] jackdeten — Jack detect enable
    0=DISABLE; 1=ENABLE
  [22:21] seldetadcdy — Select the delay time to pull low the micdet when jack removal
    0=0_5_MS; 1=1_MS; 2=1_5_MS; 3=2_MS
  [20] micadcen — Microphone detect ADC enable
    0=DISABLED; 1=ENABLED
  [19] popfree — When this bit is 0, HBIAS MICADC is controlled by registor
  [18] det_mode — MIC Detect Mode
    0=LOW (Jack in pull low); 1=HIGH (Jack in pull high)
  [17] autoplen — Enable the function to auto pull low MICDET when jack removal
    0=DISABLED; 1=ENABLED
  [16] micdetpl — When this bit is 1and AUTOPLEN is 0, the MICDET is pulled down to GND.
  [15] hmicbiasen — Headphone Microphone Bias Enable
    0=DISABLED; 1=ENABLED
  [14:13] hbiassel — HMICBIAS Voltage Level Select
    0=1_88_V; 1=2_09_V; 2=2_33_V; 3=2_55_V
  [12] hmic_bias_chopper_en — HMIC BIAS Chopper Enable
    0=DISABLED; 1=ENABLED
  [11:10] hmic_bias_chopper_clk_sel — HMIC BIAS Chopper Clock Select
    0=250KHZ; 1=500KHZ; 2=1MHZ; 3=2MHZ
  [7] mmicbiasen — Master Microphone Bias Enable
    0=DISABLED; 1=ENABLED
  [6:5] mbiassel — MMICBIAS Voltage Level Select
    0=1_88_V; 1=2_09_V; 2=2_33_V; 3=2_50_V
  [4] mmic_bias_chopper_en — MMIC BIAS Chopper Enable
    0=DISABLED; 1=ENABLED
  [3:2] mmic_bias_chopper_clk_sel — MMIC BIAS Chopper Clock Select
    0=250KHZ; 1=500KHZ; 2=1MHZ; 3=2MHZ
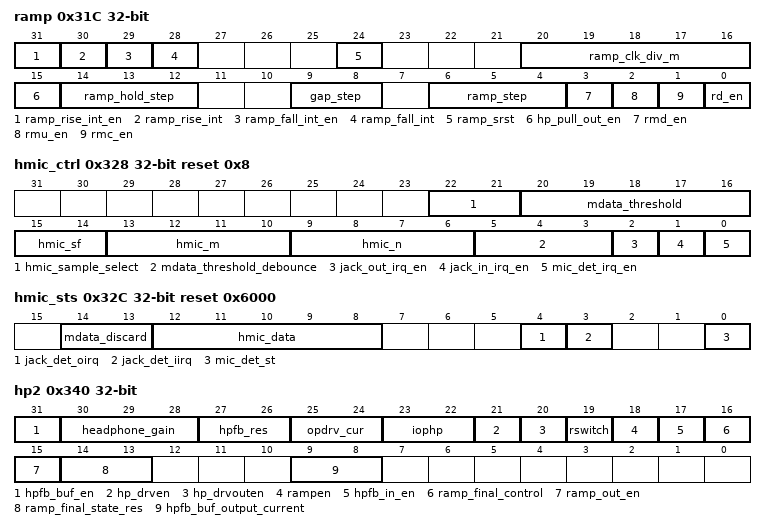
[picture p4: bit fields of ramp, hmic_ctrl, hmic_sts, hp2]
0x31C ramp — BIAS Analog Control Register
  [31] ramp_rise_int_en — RAMP Rise Interrupt Enable
    0=DISABLE; 1=ENABLE
  [30] ramp_rise_int — RK Increase Upward Finish and Rampen Pull Down Instruction
    0=NO_PENDING; 1=PENDING
  [29] ramp_fall_int_en — RAMP Fall Int Enable
    0=DISABLE; 1=ENABLE
  [28] ramp_fall_int — RK Downward Decrease Finish and Rampen Pull Down Instruction
    0=NO_PENDING; 1=PENDING
  [24] ramp_srst — Ramp Soft Reset
    0=DISABLE; 1=ENABLE
  [20:16] ramp_clk_div_m — Analog Ramp Clk Div Freq Value : M (from 0 to 31, Default: 24). . Ana_Ramp_Clk= 24MHz/(M+1) . Default Ramp Clk Freq: 24MHz/(24+1)=960 kHz
  [15] hp_pull_out_en — Headphone Pullout Enable
    0=DISABLE; 1=ENABLE
  [14:12] ramp_hold_step — Ramp Hold Step . Ramp Hold Time = Ramp Hold Step/Ramp Clk Freq
    0=S9600; 1=S19200; 2=S38400; 3=S76800; 4=S96000; 5=S115200; 6=S153600; 7=S192000
  [9:8] gap_step
    {v}=RAMP_STEP_X{v+1} (v=0..3)
  [6:4] ramp_step — RK Frequency Gear, Control Ramp Rise/Fall Total Time . Ramp Rise/Fall Total Time = (Ramp Step/Ramp Clk Freq)*4096
    0=S20; 1=S30; 2=S40; 3=S60; 4=S80; 5=S120; 6=S160; 7=S240
  [3] rmd_en — Ramp Manual Down Enable
    0=DISABLE; 1=ENABLE
  [2] rmu_en — Ramp Manual Up Enable
    0=DISABLE; 1=ENABLE
  [1] rmc_en — Ramp Manual Control Enable
    0=DISABLE; 1=ENABLE
  [0] rd_en — Ramp Digital Enable
    0=DISABLE; 1=ENABLE
0x320 bias reset 0x80 — BIAS Analog Control Register
  [7:0] biasdata — Bias Current Register Setting Data
0x328 hmic_ctrl reset 0x8 — HMIC Control Register
  [22:21] hmic_sample_select — Down Sample Setting Select
    0=BY_1 (Down by 1, 128 Hz); 1=BY_2 (Down by 2, 64 Hz); 2=BY_4 (Down by 4, 32 Hz); 3=BY_8 (Down by 8, 16 Hz)
  [20:16] mdata_threshold — MIC DET EN Threshold Value
  [15:14] hmic_sf — HMIC Smooth Filter setting
    0=BYPASS; 1=MEAN_2 ((x1+x2)/2); 2=MEAN_4 ((x1+x2+x3+x4)/4); 3=MEAN_8 ((x1+x2+x3+x4+x5+x6+x7+x8)/8)
  [13:10] hmic_m — Debounce when the MIC Key down or up. (HMIC_M + 1) sample data
  [9:6] hmic_n — Debounce when earphone plug in or pull out 125 ms to 2 s
  [5:3] mdata_threshold_debounce
  [2] jack_out_irq_en — MIC Detect Interrupt Set
    0=DISABLED; 1=ENABLED
  [1] jack_in_irq_en — MIC Detect Interrupt Set
    0=DISABLED; 1=ENABLED
  [0] mic_det_irq_en — MIC Detect Interrupt Set
    0=DISABLED; 1=ENABLED
0x32C hmic_sts reset 0x6000 — HMIC Status Register
  [14:13] mdata_discard — After MIC DATA data is received, the first N-data will be discarded.
    0=NONE (None discarded); 1=1_DATA (1-data discarded); 2=2_DATA (2-data discarded); 3=4_DATA (4-data discarded)
  [12:8] hmic_data ro — HMIC Average Data
  [4] jack_det_oirq write-1-clears — Jack output detect pending interrupt
    0=NO_PENDING (No Pending IRQ); 1=PENDING (Pending IRQ)
  [3] jack_det_iirq write-1-clears — Jack input detect pending interrupt
    0=NO_PENDING (No Pending IRQ); 1=PENDING (Pending IRQ)
  [0] mic_det_st write-1-clears — MIC detect pending interrupt
    0=NO_PENDING (No pending IRQ); 1=PENDING (Pending IRQ)
0x340 hp2 — Headphone2 Analog Control Register
  [31] hpfb_buf_en — Headphone Feedback Buffer OP Enable
    0=DISABLE; 1=ENABLE
  [30:28] headphone_gain
    0=DB0; 1=DB6; 2=DB12; 3=DB18; 4=DB24; 5=DB30; 6=DB36; 7=DB42
  [27:26] hpfb_res — Headphone Feedback Big Resistor Control
    0=R880K; 1=R1000K; 2=R1080K; 3=R1200K
  [25:24] opdrv_cur — Headphone OP Output Stage Current Setting
    0=MIN; 3=MAX
  [23:22] iophp — Headphone L/R OP Bias Current Select
    {v}=C{v+6}U (v=0..3)
  [21] hp_drven — Headphone Driver Enable
    0=DISABLE; 1=ENABLE
  [20] hp_drvouten — Headphone Driver Output Enable
    0=DISABLE; 1=ENABLE
  [19] rswitch
    0=HPOUT; 1=VRA1
  [18] rampen — Ramp DAC Enable
    0=DISABLE; 1=ENABLE
  [17] hpfb_in_en — Headphone Feedback PAD IN Switch Enable
    0=DISABLE; 1=ENABLE
  [16] ramp_final_control — Headphone Ramp Final Step Control
    0=SELECT_RAMP; 1=SELECT_HPFB_BUFFER
  [15] ramp_out_en — Ramp Output Switch Enable
    0=DISABLE; 1=ENABLE
  [14:13] ramp_final_state_res — Ramp Final State Resistor
    0=R2500; 1=R5K; 2=R10K; 3=R20K
  [9:8] hpfb_buf_output_current — Headphone Feedback Buffer Output Current Select . I = 7uA
    0=I35; 1=I28; 2=I45; 3=I38
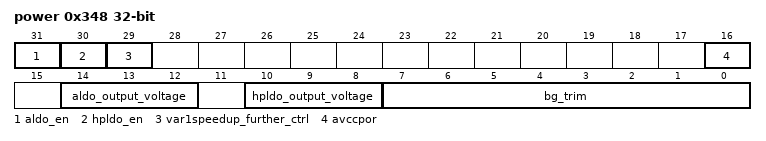
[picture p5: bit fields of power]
0x348 power — POWER Analog Control Register . The register is not controlled by the clock and reset of Audio Codec, only controlled by the clock and reset of system bus.
  [31] aldo_en — ALDO Enable
    0=DISABLE; 1=ENABLE
  [30] hpldo_en — HPLDO Enable
    0=DISABLE; 1=ENABLE
  [29] var1speedup_further_ctrl — VRA1 Speedup Down Further Control In Adda Analog
    0=DIGITAL; 1=MANUAL
  [16] avccpor ro — AVCCPOR Monitor
  [14:12] aldo_output_voltage — ALDO Output Voltage Control
    0=V165; 1=V170; 2=V175; 3=V180; 4=V185; 5=V190; 6=V195; 7=V200
  [10:8] hpldo_output_voltage — HPLDO Output Voltage Control
    values as aldo_output_voltage
  [7:0] bg_trim — BG Output Voltage Trimming . Only low 6-bit is used. The BG output voltage range is from 0.7 V to 1.208 V
